# LPC18xx register map
File version: 18
Registers are 32-bit, read-write, reset 0x0 unless marked. A register's access mark holds for its fields unless they carry their own. Offsets are from the block's base; [hi:lo] are bit positions; {n}, {i} and the like mark numbered series; 'fields as' and 'values as' point back to an identical list.

## SCU — Product name title=UM10430 Chapter title=LPC18xx System Control Unit (SCU) Modification date=6/8/2011 Major revision=0 Minor revision=10
Base 0x40086000
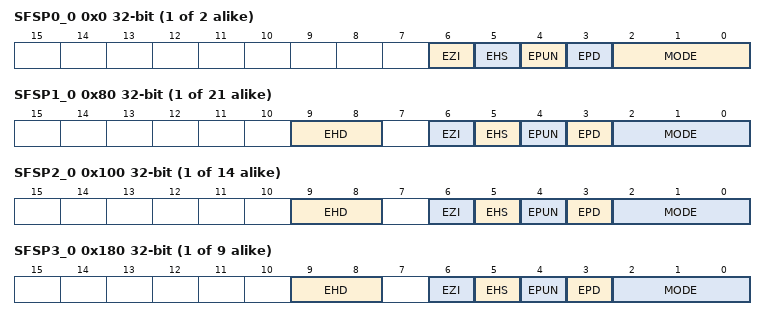
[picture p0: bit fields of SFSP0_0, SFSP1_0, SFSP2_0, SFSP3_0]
{0x0+4i} SFSP0_{i} (i=0..1) — Pin configuration register for pins P0
  [6] EZI — Input buffer enable. The input buffer is disabled by default at reset but must be enabled to transfer data from the I/O buffer to the pad.
    0=DISABLE_INPUT_BUFFER; 1=ENABLE_INPUT_BUFFER
  [5] EHS — Slew rate
    0=SLOW; 1=FAST
  [4] EPUN — Disable pull-up resistor at pad. By default, the pull-up resistor is enabled at reset.
    0=ENABLE_PULL_UP; 1=DISABLE_PULL_UP
  [3] EPD — Enable pull-down resistor at pad
    0=DISABLE_PULL_DOWN_; 1=ENABLE_PULL_DOWN_
  [2:0] MODE — Select pin function
    0=FUNCTION_0_DEFAULT); {v}=FUNCTION_{v} (v=1..7)
{0x80+4i} SFSP1_{i} (i=0..20) — Pin configuration register for pins P1
  [9:8] EHD — Select drive strength
    0=STANDARD_DRIVE_4_MA (Standard drive: 4 mA drive strength); 1=MEDIUM_DRIVE_8_MA_D (Medium drive: 8 mA drive strength); 2=HIGH_DRIVE_14_MA_DR (High drive: 14 mA drive strength); 3=ULTRA_HIGH_DRIVE_20 (Ultra-high drive: 20 mA drive strength)
  [6] EZI — Input buffer enable. The input buffer is disabled by default at reset but must be enabled to transfer data from the I/O buffer to the pad.
    0=DISABLE_INPUT_BUFFER; 1=ENABLE_INPUT_BUFFER
  [5] EHS — Slew rate
    0=SLOW; 1=FAST
  [4] EPUN — Disable pull-up resistor at pad. By default, the pull-up resistor is enabled at reset.
    0=ENABLE_PULL_UP; 1=DISABLE_PULL_UP
  [3] EPD — Enable pull-down resistor at pad
    0=DISABLE_PULL_DOWN_; 1=ENABLE_PULL_DOWN_
  [2:0] MODE — Select pin function
    0=FUNCTION_0_DEFAULT); {v}=FUNCTION_{v} (v=1..7)
{0x100+4i} SFSP2_{i} (i=0..13) — Pin configuration register for pins P2
  fields as SFSP1_0
{0x180+4i} SFSP3_{i} (i=0..8) — Pin configuration register for pins P3
  fields as SFSP1_0
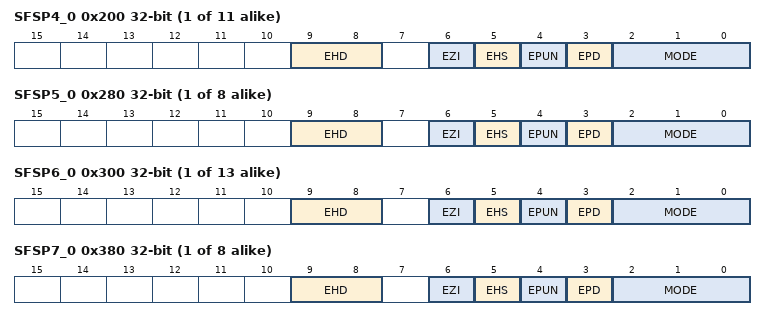
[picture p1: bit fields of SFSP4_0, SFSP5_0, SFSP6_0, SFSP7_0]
{0x200+4i} SFSP4_{i} (i=0..10) — Pin configuration register for pins P4
  fields as SFSP1_0
{0x280+4i} SFSP5_{i} (i=0..7) — Pin configuration register for pins P5
  fields as SFSP1_0
{0x300+4i} SFSP6_{i} (i=0..12) — Pin configuration register for pins P6
  fields as SFSP1_0
{0x380+4i} SFSP7_{i} (i=0..7) — Pin configuration register for pins P7
  fields as SFSP1_0
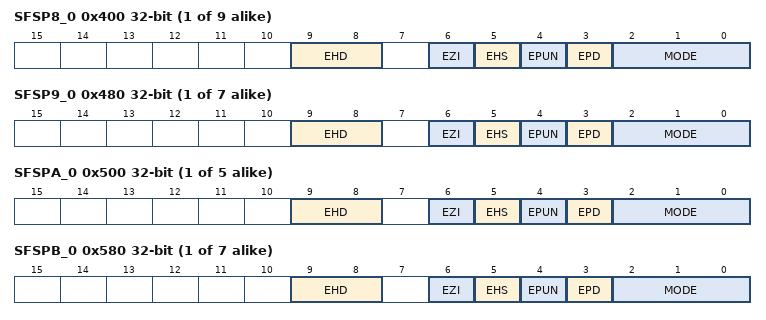
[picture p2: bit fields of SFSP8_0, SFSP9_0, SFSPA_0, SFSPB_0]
{0x400+4i} SFSP8_{i} (i=0..8) — Pin configuration register for pins P8
  fields as SFSP1_0
{0x480+4i} SFSP9_{i} (i=0..6) — Pin configuration register for pins P9
  fields as SFSP1_0
{0x500+4i} SFSPA_{i} (i=0..4) — Pin configuration register for pins PA
  fields as SFSP1_0
{0x580+4i} SFSPB_{i} (i=0..6) — Pin configuration register for pins PB
  fields as SFSP1_0
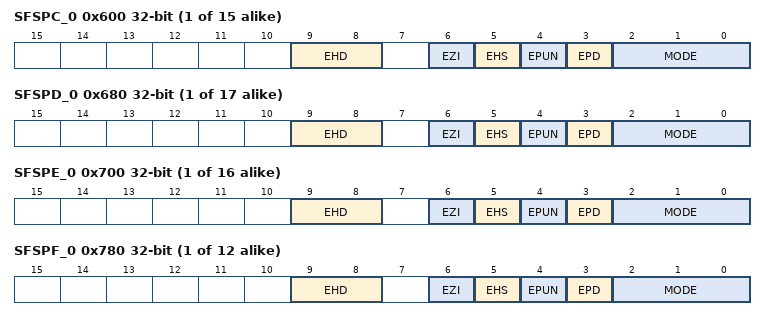
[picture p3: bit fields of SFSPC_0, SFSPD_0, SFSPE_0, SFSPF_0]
{0x600+4i} SFSPC_{i} (i=0..14) — Pin configuration register for pins PC
  fields as SFSP1_0
{0x680+4i} SFSPD_{i} (i=0..16) — Pin configuration register for pins PD
  fields as SFSP1_0
{0x700+4i} SFSPE_{i} (i=0..15) — Pin configuration register for pins PE
  fields as SFSP1_0
{0x780+4i} SFSPF_{i} (i=0..11) — Pin configuration register for pins PF
  fields as SFSP1_0
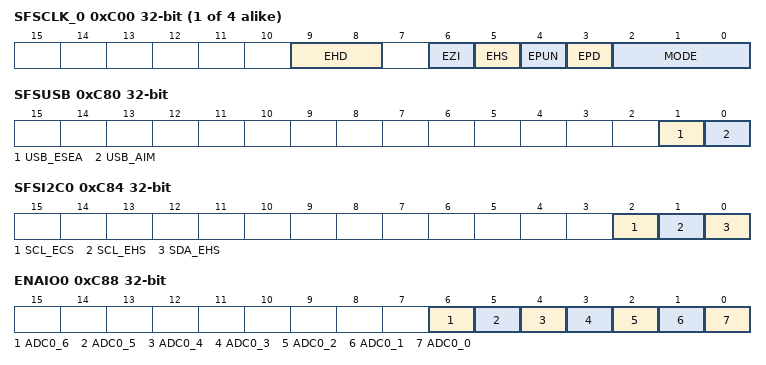
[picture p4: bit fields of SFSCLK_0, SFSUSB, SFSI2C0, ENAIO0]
{0xC00+4i} SFSCLK_{i} (i=0..3) — Pin configuration register for pins CLK
  fields as SFSP1_0
0xC80 SFSUSB — Pin configuration register for
  [1] USB_ESEA — Control signal for differential input or single input
    0=RESERVED_DO_NOT_USE; 1=SINGLE_INPUT_AIP_EN (Single input AIP. Enables USB1.)
  [0] USB_AIM — Differential data input AIP/AIM 0 = Going LOW with full speed edge rate 1 = Going HIGH with full speed edge rate
    0=GOING_LOW_WITH_FULL_ (Going LOW with full speed edge rate); 1=GOING_HIGH_WITH_FULL (Going HIGH with full speed edge rate)
0xC84 SFSI2C0 — Pin configuration register for I 2C0-bus pins
  [2] SCL_ECS — Direction (only applies if SCL_EHS = 1)
    0=RECEIVE; 1=TRANSMIT
  [1] SCL_EHS — Configures I2C0-bus speed for SCL0 pin
  [0] SDA_EHS — Configures I2C0-bus speed for SDA0 pin
    0=STANDARD/FAST_MODE_ (Standard/Fast mode (400 kbit/s)); 1=HIGH_SPEED_MODE_3_4 (High-speed mode (3.4 Mbit/s))
0xC88 ENAIO0 — ADC0 function select register
  [6] ADC0_6 — Select ADC0_6
    0=ANALOG_FUNCTION_ADC0 (Analog function ADC0_6 selected on pin PB_6.); 1=DIGITAL_FUNCTION_SEL (Digital function selected on pin PB_6.)
  [5] ADC0_5 — Select ADC0_5
    0=ANALOG_FUNCTION_ADC0 (Analog function ADC0_5 selected on pin PF_10.); 1=DIGITAL_FUNCTION_SEL (Digital function selected on pin PF_10.)
  [4] ADC0_4 — Select ADC0_4
    0=ANALOG_FUNCTION_ADC0 (Analog function ADC0_4 selected on pin P7_4.); 1=DIGITAL_FUNCTION_SEL (Digital function selected on pin P7_4.)
  [3] ADC0_3 — Select ADC0_3
    0=ANALOG_FUNCTION_ADC0 (Analog function ADC0_3 selected on pin P7_5.); 1=DIGITAL_FUNCTION_SEL (Digital function selected on pin P7_5.)
  [2] ADC0_2 — Select ADC0_2
    0=ANALOG_FUNCTION_ADC0 (Analog function ADC0_2 selected on pin PF_8.); 1=DIGITAL_FUNCTION_SEL (Digital function selected on pin PF_8.)
  [1] ADC0_1 — Select ADC0_1
    0=ANALOG_FUNCTION_ADC0 (Analog function ADC0_1 selected on pin P4_1.); 1=DIGITAL_FUNCTION_SEL (Digital function selected on pin P4_1.)
  [0] ADC0_0 — Select ADC0_0
    0=ANALOG_FUNCTION_ADC0 (Analog function ADC0_0 selected on pin P4_3.); 1=DIGITAL_FUNCTION_SEL (Digital function selected on pin P4_3.)
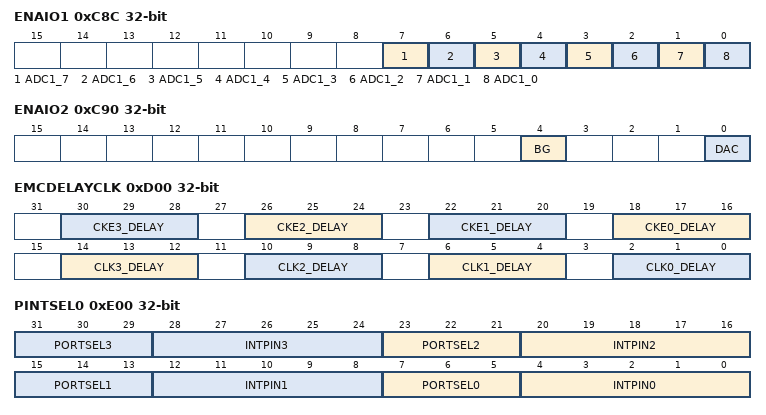
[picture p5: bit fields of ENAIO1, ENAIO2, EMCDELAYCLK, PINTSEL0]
0xC8C ENAIO1 — ADC1 function select register
  [7] ADC1_7 — Select ADC1_7
    0=ANALOG_FUNCTION_ADC1 (Analog function ADC1_7 selected on pin PF_7.); 1=DIGITAL_FUNCTION_SEL (Digital function selected on pin PF_7.)
  [6] ADC1_6 — Select ADC1_6
    0=ANALOG_FUNCTION_ADC1 (Analog function ADC1_6 selected on pin P7_7.); 1=DIGITAL_FUNCTION_SEL (Digital function selected on pin P7_7.)
  [5] ADC1_5 — Select ADC1_5
    0=ANALOG_FUNCTION_ADC1 (Analog function ADC1_5 selected on pin PF_11.); 1=DIGITAL_FUNCTION_SEL (Digital function selected on pin PF_11.)
  [4] ADC1_4 — Select ADC1_4
    0=ANALOG_FUNCTION_ADC1 (Analog function ADC1_4 selected on pin PF_5.); 1=DIGITAL_FUNCTION_SEL (Digital function selected on pin PF_5.)
  [3] ADC1_3 — Select ADC1_3
    0=ANALOG_FUNCTION_ADC1 (Analog function ADC1_3 selected on pin PF_6.); 1=DIGITAL_FUNCTION_SEL (Digital function selected on pin PF_6.)
  [2] ADC1_2 — Select ADC1_2
    0=ANALOG_FUNCTION_ADC1 (Analog function ADC1_2 selected on pin PF_9.); 1=DIGITAL_FUNCTION_SEL (Digital function selected on pin PF_9.)
  [1] ADC1_1 — Select ADC1_1
    0=ANALOG_FUNCTION_ADC1 (Analog function ADC1_1 selected on pin PC_0.); 1=DIGITAL_FUNCTION_SEL (Digital function selected on pin PC_0.)
  [0] ADC1_0 — Select ADC1_0
    0=ANALOG_FUNCTION_ADC1 (Analog function ADC1_0 selected on pin PC_3.); 1=DIGITAL_FUNCTION_SEL (Digital function selected on pin PC_3.)
0xC90 ENAIO2 — Analog function select register
  [4] BG — Select bandgap output
    0=BANDGAP_OUTPUT_SELEC (Bandgap output selected for pin PF_7.); 1=DIGITAL_FUNCTION_SEL (Digital function selected on pin PF_7.)
  [0] DAC — Select DAC
    0=ANALOG_FUNCTION_DAC_ (Analog function DAC selected on pin P4_4.); 1=DIGITAL_FUNCTION_SEL (Digital function selected on pin P4_4.)
0xD00 EMCDELAYCLK — EMC clock delay register
  [4n+18:4n+16] CKE{n}_DELAY (n=0..3) — Delay of the EXTBUS_CKEOUT{n} clock enable output.
  [14:12] CLK3_DELAY — Delay of the EXTBUS_CLK3 clock output.
  [10:8] CLK2_DELAY — Delay of the EXTBUS_CLK2 clock output.
  [6:4] CLK1_DELAY — Delay of the EXTBUS_CLK0 clock output.
  [2:0] CLK0_DELAY — Delay of the EXTBUS_CLK0 clock output.
0xE00 PINTSEL0 — Pin interrupt select register for pin interrupts 0 to 3.
  [8n+7:8n+5] PORTSEL{n} (n=0..3) — Pin interrupt {n}: Select the port for the pin number to be selected in the INTPIN{n} bits of this register.
    {v}=GPIO_PORT_{v} (v=0..7)
  [8n+4:8n] INTPIN{n} (n=0..3) — Pint interrupt {n}: Select the pin number within the GPIO port selected by the PORTSEL{n} bit in this register.
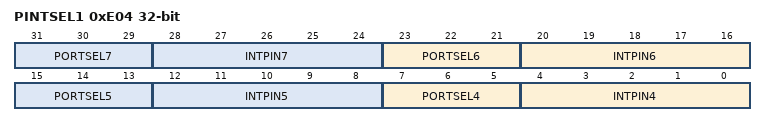
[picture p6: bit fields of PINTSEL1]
0xE04 PINTSEL1 — Pin interrupt select register for pin interrupts 4 to 7.
  [8n-25:8n-27] PORTSEL{n} (n=4..7) — Pin interrupt {n}: Select the port for the pin number to be selected in the INTPIN{n} bits of this register.
    {v}=GPIO_PORT_{v} (v=0..7)
  [8n-28:8n-32] INTPIN{n} (n=4..7) — Pint interrupt {n}: Select the pin number within the GPIO port selected by the PORTSEL{n} bit in this register.
